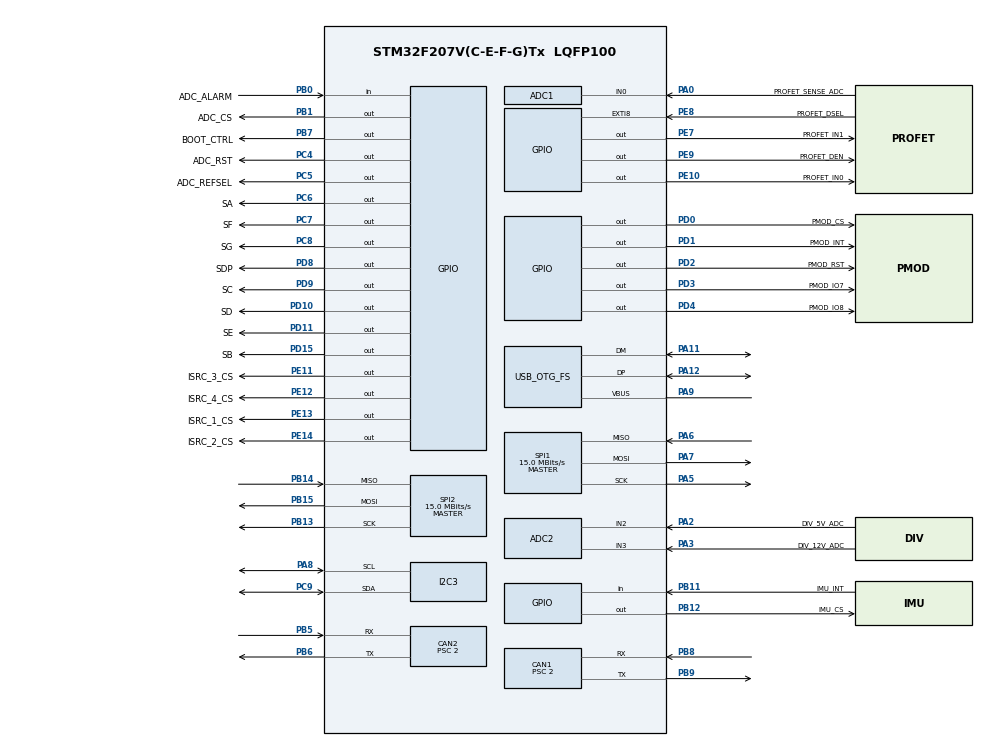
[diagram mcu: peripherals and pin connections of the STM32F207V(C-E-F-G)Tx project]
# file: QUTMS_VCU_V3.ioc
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ADC1.Channel-0\#ChannelRegularConversion=ADC_CHANNEL_0
ADC1.ClockPrescaler=ADC_CLOCK_SYNC_PCLK_DIV4
ADC1.NbrOfConversionFlag=1
ADC1.Rank-0\#ChannelRegularConversion=1
ADC1.SamplingTime-0\#ChannelRegularConversion=ADC_SAMPLETIME_3CYCLES
ADC1.master=1
ADC2.Channel-0\#ChannelRegularConversion=ADC_CHANNEL_2
ADC2.ClockPrescaler=ADC_CLOCK_SYNC_PCLK_DIV4
ADC2.NbrOfConversionFlag=1
ADC2.Rank-0\#ChannelRegularConversion=1
ADC2.SamplingTime-0\#ChannelRegularConversion=ADC_SAMPLETIME_3CYCLES
CAN1.BS1=CAN_BS1_12TQ
CAN1.BS2=CAN_BS2_2TQ
CAN1.CalculateBaudRate=999999
CAN1.CalculateTimeBit=1000
CAN1.CalculateTimeQuantum=66.66666666666667
CAN1.Prescaler=2
CAN2.BS1=CAN_BS1_12TQ
CAN2.BS2=CAN_BS2_2TQ
CAN2.CalculateBaudRate=999999
CAN2.CalculateTimeBit=1000
CAN2.CalculateTimeQuantum=66.66666666666667
CAN2.Prescaler=2
FREERTOS.Tasks01=defaultTask,24,128,StartDefaultTask,Default,NULL,Dynamic,NULL,NULL
IWDG.Prescaler=IWDG_PRESCALER_256
Mcu.Family=STM32F2
Mcu.Name=STM32F207V(C-E-F-G)Tx
Mcu.Package=LQFP100
NVIC.CAN1_RX0_IRQn=true\:5\:0\:false\:false\:true\:true\:true\:true\:true
NVIC.CAN1_RX1_IRQn=true\:5\:0\:false\:false\:true\:true\:true\:true\:true
NVIC.CAN1_TX_IRQn=true\:5\:0\:false\:false\:true\:true\:true\:true\:true
NVIC.CAN2_RX0_IRQn=true\:5\:0\:false\:false\:true\:true\:true\:true\:true
NVIC.CAN2_RX1_IRQn=true\:5\:0\:false\:false\:true\:true\:true\:true\:true
NVIC.CAN2_TX_IRQn=true\:5\:0\:false\:false\:true\:true\:true\:true\:true
NVIC.OTG_FS_IRQn=true\:5\:0\:false\:false\:true\:true\:false\:true\:true
NVIC.PriorityGroup=NVIC_PRIORITYGROUP_4
NVIC.SPI1_IRQn=true\:5\:0\:false\:false\:true\:true\:true\:true\:true
NVIC.TIM2_IRQn=true\:5\:0\:false\:false\:true\:true\:true\:true\:true
NVIC.TIM3_IRQn=true\:5\:0\:false\:false\:true\:true\:true\:true\:true
NVIC.TIM5_IRQn=true\:5\:0\:false\:false\:true\:true\:true\:true\:true
PA0-WKUP.GPIO_Label=PROFET_SENSE_ADC
PA0-WKUP.Signal=ADCx_IN0
PA11.Mode=Device_Only
PA11.Signal=USB_OTG_FS_DM
PA12.Mode=Device_Only
PA12.Signal=USB_OTG_FS_DP
PA13.Mode=JTAG_5_pins
PA13.Signal=SYS_JTMS-SWDIO
PA14.Mode=JTAG_5_pins
PA14.Signal=SYS_JTCK-SWCLK
PA15.Mode=JTAG_5_pins
PA15.Signal=SYS_JTDI
PA2.GPIO_Label=DIV_5V_ADC
PA2.Signal=ADCx_IN2
PA3.GPIO_Label=DIV_12V_ADC
PA3.Signal=ADCx_IN3
PA5.GPIO_PuPd=GPIO_PULLDOWN
PA5.Mode=Full_Duplex_Master
PA5.Signal=SPI1_SCK
PA6.Mode=Full_Duplex_Master
PA6.Signal=SPI1_MISO
PA7.Mode=Full_Duplex_Master
PA7.Signal=SPI1_MOSI
PA8.Mode=I2C
PA8.Signal=I2C3_SCL
PA9.Mode=Activate_VBUS
PA9.Signal=USB_OTG_FS_VBUS
PB0.GPIO_Label=ADC_ALARM
PB0.Signal=GPIO_Input
PB1.GPIO_Label=ADC_CS
PB1.GPIO_PuPd=GPIO_PULLUP
PB1.Signal=GPIO_Output
PB11.GPIO_Label=IMU_INT
PB11.Signal=GPIO_Input
PB12.GPIO_Label=IMU_CS
PB12.GPIO_PuPd=GPIO_PULLUP
PB12.Signal=GPIO_Output
PB13.Mode=Full_Duplex_Master
PB13.Signal=SPI2_SCK
PB14.Mode=Full_Duplex_Master
PB14.Signal=SPI2_MISO
PB15.Mode=Full_Duplex_Master
PB15.Signal=SPI2_MOSI
PB3.Mode=JTAG_5_pins
PB3.Signal=SYS_JTDO-SWO
PB4.Mode=JTAG_5_pins
PB4.Signal=SYS_JTRST
PB5.Mode=CAN_Activate
PB5.Signal=CAN2_RX
PB6.Mode=CAN_Activate
PB6.Signal=CAN2_TX
PB7.GPIO_Label=BOOT_CTRL
PB7.GPIO_PuPd=GPIO_PULLDOWN
PB7.Signal=GPIO_Output
PB8.Mode=CAN_Activate
PB8.Signal=CAN1_RX
PB9.Mode=CAN_Activate
PB9.Signal=CAN1_TX
PC4.GPIO_Label=ADC_RST
PC4.Signal=GPIO_Output
PC5.GPIO_Label=ADC_REFSEL
PC5.Signal=GPIO_Output
PC6.GPIO_Label=SA
PC6.Signal=GPIO_Output
PC7.GPIO_Label=SF
PC7.Signal=GPIO_Output
PC8.GPIO_Label=SG
PC8.Signal=GPIO_Output
PC9.Mode=I2C
PC9.Signal=I2C3_SDA
PD0.GPIO_Label=PMOD_CS
PD0.GPIO_PuPd=GPIO_NOPULL
PD0.Signal=GPIO_Output
PD1.GPIO_Label=PMOD_INT
PD1.Signal=GPIO_Output
PD10.GPIO_Label=SD
PD10.Signal=GPIO_Output
PD11.GPIO_Label=SE
PD11.Signal=GPIO_Output
PD15.GPIO_Label=SB
PD15.Signal=GPIO_Output
PD2.GPIO_Label=PMOD_RST
PD2.Signal=GPIO_Output
PD3.GPIO_Label=PMOD_IO7
PD3.Signal=GPIO_Output
PD4.GPIO_Label=PMOD_IO8
PD4.Signal=GPIO_Output
PD8.GPIO_Label=SDP
PD8.Signal=GPIO_Output
PD9.GPIO_Label=SC
PD9.Signal=GPIO_Output
PE10.GPIO_Label=PROFET_IN0
PE10.Signal=GPIO_Output
PE11.GPIO_Label=ISRC_3_CS
PE11.GPIO_PuPd=GPIO_PULLUP
PE11.Signal=GPIO_Output
PE12.GPIO_Label=ISRC_4_CS
PE12.GPIO_PuPd=GPIO_PULLUP
PE12.Signal=GPIO_Output
PE13.GPIO_Label=ISRC_1_CS
PE13.GPIO_PuPd=GPIO_PULLUP
PE13.Signal=GPIO_Output
PE14.GPIO_Label=ISRC_2_CS
PE14.GPIO_PuPd=GPIO_PULLUP
PE14.Signal=GPIO_Output
PE7.GPIO_Label=PROFET_IN1
PE7.Signal=GPIO_Output
PE8.GPIO_Label=PROFET_DSEL
PE8.Signal=GPXTI8
PE9.GPIO_Label=PROFET_DEN
PE9.Signal=GPIO_Output
PH0-OSC_IN.Mode=HSE-External-Oscillator
PH0-OSC_IN.Signal=RCC_OSC_IN
PH1-OSC_OUT.Mode=HSE-External-Oscillator
PH1-OSC_OUT.Signal=RCC_OSC_OUT
ProjectManager.HeapSize=0x1000
ProjectManager.StackSize=0x200
ProjectManager.TargetToolchain=STM32CubeIDE
RCC.48MHZClocksFreq_Value=48000000
RCC.AHBFreq_Value=120000000
RCC.APB1CLKDivider=RCC_HCLK_DIV4
RCC.APB1Freq_Value=30000000
RCC.APB1TimFreq_Value=60000000
RCC.APB2CLKDivider=RCC_HCLK_DIV2
RCC.APB2Freq_Value=60000000
RCC.APB2TimFreq_Value=120000000
RCC.CortexFreq_Value=120000000
RCC.HCLKFreq_Value=120000000
RCC.HSE_VALUE=20000000
RCC.HSI_VALUE=16000000
RCC.LSE_VALUE=32768
RCC.PLLQ=5
RCC.PLLSourceVirtual=RCC_PLLSOURCE_HSE
RCC.SYSCLKFreq_VALUE=120000000
RCC.SYSCLKSource=RCC_SYSCLKSOURCE_PLLCLK
RCC.VCOOutputFreq_Value=240000000
SH.ADCx_IN0.0=ADC1_IN0,IN0
SH.ADCx_IN2.0=ADC2_IN2,IN2
SH.ADCx_IN3.0=ADC2_IN3,IN3
SPI1.BaudRatePrescaler=SPI_BAUDRATEPRESCALER_4
SPI1.CLKPhase=SPI_PHASE_2EDGE
SPI1.CLKPolarity=SPI_POLARITY_LOW
SPI1.CalculateBaudRate=15.0 MBits/s
SPI1.Direction=SPI_DIRECTION_2LINES
SPI1.Mode=SPI_MODE_MASTER
SPI1.VirtualType=VM_MASTER
SPI2.BaudRatePrescaler=SPI_BAUDRATEPRESCALER_2
SPI2.CalculateBaudRate=15.0 MBits/s
SPI2.Direction=SPI_DIRECTION_2LINES
SPI2.Mode=SPI_MODE_MASTER
SPI2.VirtualType=VM_MASTER
TIM2.AutoReloadPreload=TIM_AUTORELOAD_PRELOAD_ENABLE
TIM2.Period=99
TIM2.Prescaler=59
TIM3.Period=199
TIM3.Prescaler=59
TIM5.AutoReloadPreload=TIM_AUTORELOAD_PRELOAD_ENABLE
TIM5.Period=1999
TIM5.Prescaler=59
USB_DEVICE.CLASS_NAME_FS=CDC
USB_DEVICE.VirtualMode-CDC_FS=Cdc
USB_DEVICE.VirtualModeFS=Cdc_FS
USB_OTG_FS.VirtualMode=Device_Only
VP_FREERTOS_VS_CMSIS_V2.Mode=CMSIS_V2
VP_IWDG_VS_IWDG.Mode=IWDG_Activate
VP_TIM2_VS_ClockSourceINT.Mode=Internal
VP_TIM3_VS_ClockSourceINT.Mode=Internal
VP_TIM5_VS_ClockSourceINT.Mode=Internal
VP_USB_DEVICE_VS_USB_DEVICE_CDC_FS.Mode=CDC_FS
board=custom

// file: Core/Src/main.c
/* USER CODE BEGIN Header */
/**
  ******************************************************************************
  * @file           : main.c
  * @brief          : Main program body
  ******************************************************************************
  * @attention
  *
  * Copyright (c) 2023 STMicroelectronics.
  * All rights reserved.
  *
  * This software is licensed under terms that can be found in the LICENSE file
  * in the root directory of this software component.
  * If no LICENSE file comes with this software, it is provided AS-IS.
  *
  ******************************************************************************
  */
/* USER CODE END Header */
#include "main.h"
#include "cmsis_os.h"
#include "adc.h"
#include "can.h"
#include "i2c.h"
#include "spi.h"
#include "tim.h"
#include "usb_device.h"
#include "gpio.h"

/* USER CODE BEGIN Includes */
#include "7Seg.h"
/* USER CODE END Includes */

void SystemClock_Config(void);
void MX_FREERTOS_Init(void);

int main(void)
{

  /* MCU Configuration--------------------------------------------------------*/

  /* Reset of all peripherals, Initializes the Flash interface and the Systick. */
  HAL_Init();

  /* Configure the system clock */
  SystemClock_Config();

  /* Initialize all configured peripherals */
  MX_GPIO_Init();
  MX_CAN1_Init();
  MX_ADC1_Init();
  MX_ADC2_Init();
  MX_CAN2_Init();
  MX_I2C3_Init();
  MX_SPI1_Init();
  MX_SPI2_Init();
  MX_TIM2_Init();
  MX_TIM5_Init();
  MX_TIM3_Init();
  /* USER CODE BEGIN 2 */
  set_7seg(VCU_CURRENT_ID, false);
//  HAL_TIM_Base_Start_IT(&htim3);
  /* USER CODE END 2 */

  /* Init scheduler */
  osKernelInitialize();  /* Call init function for freertos objects (in freertos.c) */
  MX_FREERTOS_Init();

  /* Start scheduler */
  osKernelStart();

  /* We should never get here as control is now taken by the scheduler */
  /* Infinite loop */
  while (1)
  {

  }
}

void SystemClock_Config(void)
{
  LL_FLASH_SetLatency(LL_FLASH_LATENCY_3);
  while(LL_FLASH_GetLatency()!= LL_FLASH_LATENCY_3)
  {
  }
  LL_RCC_HSE_Enable();

   /* Wait till HSE is ready */
  while(LL_RCC_HSE_IsReady() != 1)
  {

  }
  LL_RCC_LSI_Enable();

   /* Wait till LSI is ready */
  while(LL_RCC_LSI_IsReady() != 1)
  {

  }
  LL_RCC_PLL_ConfigDomain_SYS(LL_RCC_PLLSOURCE_HSE, LL_RCC_PLLM_DIV_16, 192, LL_RCC_PLLP_DIV_2);
  LL_RCC_PLL_ConfigDomain_48M(LL_RCC_PLLSOURCE_HSE, LL_RCC_PLLM_DIV_16, 192, LL_RCC_PLLQ_DIV_5);
  LL_RCC_PLL_Enable();

   /* Wait till PLL is ready */
  while(LL_RCC_PLL_IsReady() != 1)
  {

  }
  LL_RCC_SetAHBPrescaler(LL_RCC_SYSCLK_DIV_1);
  LL_RCC_SetAPB1Prescaler(LL_RCC_APB1_DIV_4);
  LL_RCC_SetAPB2Prescaler(LL_RCC_APB2_DIV_2);
  LL_RCC_SetSysClkSource(LL_RCC_SYS_CLKSOURCE_PLL);

   /* Wait till System clock is ready */
  while(LL_RCC_GetSysClkSource() != LL_RCC_SYS_CLKSOURCE_STATUS_PLL)
  {

  }
  LL_SetSystemCoreClock(120000000);

   /* Update the time base */
  if (HAL_InitTick (TICK_INT_PRIORITY) != HAL_OK)
  {
    Error_Handler();
  }
}

void Error_Handler(void)
{
  __disable_irq();
  while (1)
  {
  }
}

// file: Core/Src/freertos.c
/* USER CODE BEGIN Header */
/**
  ******************************************************************************
  * File Name          : freertos.c
  * Description        : Code for freertos applications
  ******************************************************************************
  * @attention
  *
  * Copyright (c) 2023 STMicroelectronics.
  * All rights reserved.
  *
  * This software is licensed under terms that can be found in the LICENSE file
  * in the root directory of this software component.
  * If no LICENSE file comes with this software, it is provided AS-IS.
  *
  ******************************************************************************
  */
/* USER CODE END Header */

#include "FreeRTOS.h"
#include "task.h"
#include "main.h"
#include "cmsis_os.h"

/* USER CODE BEGIN Includes */
#include "tasks.h"
/* USER CODE END Includes */

/* Definitions for defaultTask */
osThreadId_t defaultTaskHandle;
const osThreadAttr_t defaultTask_attributes = {
  .name = "defaultTask",
  .stack_size = 128 * 4,
  .priority = (osPriority_t) osPriorityNormal,
};

void StartDefaultTask(void *argument);

extern void MX_USB_DEVICE_Init(void);
void MX_FREERTOS_Init(void); /* (MISRA C 2004 rule 8.1) */

void MX_FREERTOS_Init(void) {

  /* Create the thread(s) */
  /* creation of defaultTask */
  defaultTaskHandle = osThreadNew(StartDefaultTask, NULL, &defaultTask_attributes);

  /* USER CODE BEGIN RTOS_THREADS */
  setup_tasks();
  /* USER CODE END RTOS_THREADS */

}

void StartDefaultTask(void *argument)
{
  /* init code for USB_DEVICE */
  MX_USB_DEVICE_Init();
  for(;;)
  {
    osDelay(1);
  }
}
